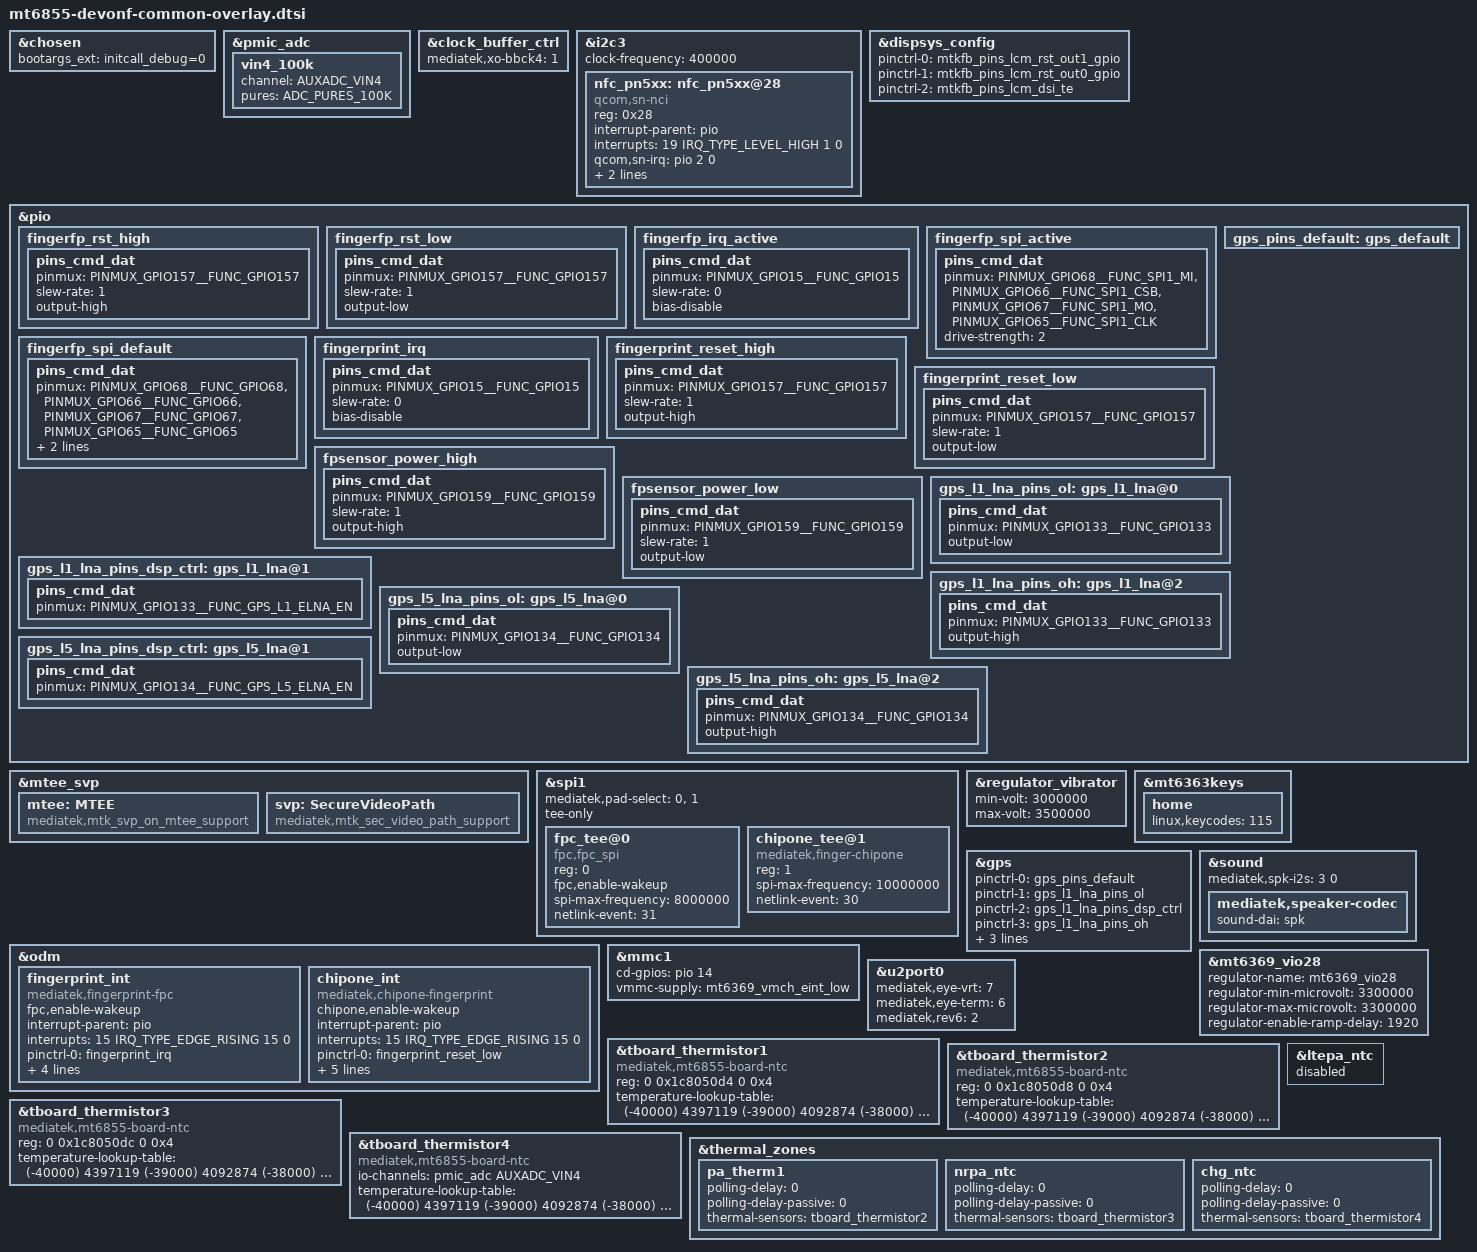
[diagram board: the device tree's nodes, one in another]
/* Copyright (c) 2020, The Linux Foundation. All rights reserved.
 *
 * This program is free software; you can redistribute it and/or modify
 * it under the terms of the GNU General Public License version 2 and
 * only version 2 as published by the Free Software Foundation.
 *
 * This program is distributed in the hope that it will be useful,
 * but WITHOUT ANY WARRANTY; without even the implied warranty of
 * MERCHANTABILITY or FITNESS FOR A PARTICULAR PURPOSE.  See the
 * GNU General Public License for more details.
 */

#include "mediatek/mt6855-moto-common-overlay.dtsi"
#include <dt-bindings/gpio/gpio.h>
#include "mediatek/devonf-display.dtsi"
#include "mediatek/devonf-charger.dtsi"
#include "mediatek/mt6855_devonf_camera_overlay.dtsi"
#include "mediatek/devonf-sar.dtsi"
#include "mediatek/devonf-audio.dtsi"
#include "mediatek/mt6855-moto-memory.dtsi"

#include <dt-bindings/iio/mt635x-auxadc.h>

&chosen {
	bootargs_ext = "initcall_debug=0";
};

&pmic_adc {
	vin4_100k {
		channel = <AUXADC_VIN4>;
		pures = <ADC_PURES_100K>;
	};
};

&clock_buffer_ctrl {
        mediatek,xo-bbck4 = <1>;
};

&i2c3 {
        status = "okay";
        clock-frequency = <400000>;
        nfc_pn5xx: nfc_pn5xx@28 {
                compatible = "qcom,sn-nci";
                reg = <0x28>;
                interrupt-parent = <&pio>;
                interrupts = <19 IRQ_TYPE_LEVEL_HIGH 1 0>;
                qcom,sn-irq = <&pio 2 0>;
                qcom,sn-ven = <&pio 161 0>;
                qcom,sn-firm = <&pio 1 0>;
                status = "okay";
        };
};

&dispsys_config {
	pinctrl-names =
		"lcm_rst_out1_gpio", "lcm_rst_out0_gpio",
		"mode_te_te";
	pinctrl-0 = <&mtkfb_pins_lcm_rst_out1_gpio>;
	pinctrl-1 = <&mtkfb_pins_lcm_rst_out0_gpio>;
	pinctrl-2 = <&mtkfb_pins_lcm_dsi_te>;
	status = "okay";
};

&pio {

	fingerfp_rst_high: fingerfp_rst_high {
		pins_cmd_dat {
			pinmux = <PINMUX_GPIO157__FUNC_GPIO157>;
			slew-rate = <1>;
			output-high;
		};
	};

	fingerfp_rst_low: fingerfp_rst_low {
		pins_cmd_dat {
			pinmux = <PINMUX_GPIO157__FUNC_GPIO157>;
			slew-rate = <1>;
			output-low;
		};
	};

	fingerfp_irq_active: fingerfp_irq_active {
		pins_cmd_dat {
			pinmux = <PINMUX_GPIO15__FUNC_GPIO15>;
			slew-rate = <0>;
			bias-disable;
		};
	};

	fingerfp_spi_active: fingerfp_spi_active {
		pins_cmd_dat {
			pinmux = <PINMUX_GPIO68__FUNC_SPI1_MI>, <PINMUX_GPIO66__FUNC_SPI1_CSB>, <PINMUX_GPIO67__FUNC_SPI1_MO>, <PINMUX_GPIO65__FUNC_SPI1_CLK>;
			drive-strength = <2>;
		};
	};

	fingerfp_spi_default: fingerfp_spi_default {
		pins_cmd_dat {
			pinmux = <PINMUX_GPIO68__FUNC_GPIO68>, <PINMUX_GPIO66__FUNC_GPIO66>, <PINMUX_GPIO67__FUNC_GPIO67>, <PINMUX_GPIO65__FUNC_GPIO65>;
			slew-rate = <1>;
			output-low;
		};
	};
	fingerprint_irq: fingerprint_irq {
		pins_cmd_dat {
			pinmux = <PINMUX_GPIO15__FUNC_GPIO15>;
			slew-rate = <0>;
			bias-disable;
		};
	};

	fingerprint_reset_high: fingerprint_reset_high {
		pins_cmd_dat {
			pinmux = <PINMUX_GPIO157__FUNC_GPIO157>;
			slew-rate = <1>;
			output-high;
		};
	};

	fingerprint_reset_low: fingerprint_reset_low {
		pins_cmd_dat {
			pinmux = <PINMUX_GPIO157__FUNC_GPIO157>;
			slew-rate = <1>;
			output-low;
		};
	};
	fpsensor_power_high: fpsensor_power_high {
		pins_cmd_dat {
			pinmux = <PINMUX_GPIO159__FUNC_GPIO159>;
			slew-rate = <1>;
			output-high;
		};
	};

	fpsensor_power_low: fpsensor_power_low {
		pins_cmd_dat {
			pinmux = <PINMUX_GPIO159__FUNC_GPIO159>;
			slew-rate = <1>;
			output-low;
		};
	};
};

/* SVP */
&mtee_svp {
	mtee: MTEE {
		compatible = "mediatek,mtk_svp_on_mtee_support";
	};
	svp: SecureVideoPath {
		compatible = "mediatek,mtk_sec_video_path_support";
	};
};

/* FINGERPRINT start */
&spi1 {
	status = "okay";
	mediatek,pad-select = <0>, <1>;
	tee-only;

	fpc_tee@0 {
		compatible = "fpc,fpc_spi";
		reg = <0>;
		fpc,enable-wakeup;
		spi-max-frequency = <8000000>;
		netlink-event = <31>;
		status = "okay";
	};

	chipone_tee@1 {
		status = "okay";
		compatible = "mediatek,finger-chipone";
		reg = <1>;
		spi-max-frequency = <10000000>;
		netlink-event = <30>;
	};
};

&odm {
	fingerprint_int: fingerprint_int {
		compatible = "mediatek,fingerprint-fpc";
		fpc,enable-wakeup;
		interrupt-parent = <&pio>;
		interrupts = <15 IRQ_TYPE_EDGE_RISING 15 0>;
		pinctrl-names = "fingerprint_irq", "fingerprint_reset_high", "fingerprint_reset_low";
		pinctrl-0 = <&fingerprint_irq>;
		pinctrl-1 = <&fingerprint_reset_high>;
		pinctrl-2 = <&fingerprint_reset_low>;
		fpc,vdd = <&pio 159 0>;
		fpc,irq = <&pio 15 0>;
		status = "okay";
	};

	chipone_int: chipone_int {
		compatible = "mediatek,chipone-fingerprint";
chipone,enable-wakeup;
		interrupt-parent = <&pio>;
		interrupts = <15 IRQ_TYPE_EDGE_RISING 15 0>;
		pinctrl-names = "fingerprint_reset_low", "fingerprint_reset_high" , "fingerprint_irq", "fpsensor_power_high", "fpsensor_power_low";
		pinctrl-0 = <&fingerprint_reset_low>;
		pinctrl-1 = <&fingerprint_reset_high>;
		pinctrl-2 = <&fingerprint_irq>;
		pinctrl-3= <&fpsensor_power_high>;
		pinctrl-4 = <&fpsensor_power_low>;
		chipone,irq = <&pio 15 0>;
		status = "okay";
	};
};

&regulator_vibrator {
	min-volt = <3000000>;
	max-volt = <3500000>;
	status = "ok";
};

&mt6363keys {
        home {
                linux,keycodes = <115>;
        };
};

/* GPS GPIO standardization start */
&pio {
	gps_pins_default: gps_default {
	};
	gps_l1_lna_pins_ol: gps_l1_lna@0 {
		pins_cmd_dat {
			pinmux = <PINMUX_GPIO133__FUNC_GPIO133>;
			output-low;
		};
	};
	gps_l1_lna_pins_dsp_ctrl: gps_l1_lna@1 {
		pins_cmd_dat {
			pinmux = <PINMUX_GPIO133__FUNC_GPS_L1_ELNA_EN>;
		};
	};
	gps_l1_lna_pins_oh: gps_l1_lna@2 {
		pins_cmd_dat {
			pinmux = <PINMUX_GPIO133__FUNC_GPIO133>;
			output-high;
		};
	};
	gps_l5_lna_pins_ol: gps_l5_lna@0 {
		pins_cmd_dat {
			pinmux = <PINMUX_GPIO134__FUNC_GPIO134>;
			output-low;
		};
	};
	gps_l5_lna_pins_dsp_ctrl: gps_l5_lna@1 {
		pins_cmd_dat {
			pinmux = <PINMUX_GPIO134__FUNC_GPS_L5_ELNA_EN>;
		};
	};
	gps_l5_lna_pins_oh: gps_l5_lna@2 {
		pins_cmd_dat {
			pinmux = <PINMUX_GPIO134__FUNC_GPIO134>;
			output-high;
		};
	};
};



&gps {
	pinctrl-names = "default",
		"gps_l1_lna_disable",
		"gps_l1_lna_dsp_ctrl",
		"gps_l1_lna_enable",
		"gps_l5_lna_disable",
		"gps_l5_lna_dsp_ctrl",
		"gps_l5_lna_enable";
	pinctrl-0 = <&gps_pins_default>;
	pinctrl-1 = <&gps_l1_lna_pins_ol>;
	pinctrl-2 = <&gps_l1_lna_pins_dsp_ctrl>;
	pinctrl-3 = <&gps_l1_lna_pins_oh>;
	pinctrl-4 = <&gps_l5_lna_pins_ol>;
	pinctrl-5 = <&gps_l5_lna_pins_dsp_ctrl>;
	pinctrl-6 = <&gps_l5_lna_pins_oh>;
	status = "okay";
};
/* GPS GPIO standardization end */

//#include "mediatek/cust_mt6855_touch_1080x2400.dtsi"
#include "mediatek/cust_mt6855_camera_v4l2.dtsi"

/delete-node/ &camera_main_two_af_mtk;

&sound {
	mediatek,spk-i2s = <3 0>;
	mediatek,speaker-codec {
		sound-dai = <&spk>;
	};
};

&mmc1 {
	cd-gpios = <&pio 14 GPIO_ACTIVE_HIGH>;
	vmmc-supply = <&mt6369_vmch_eint_low>;
};
#include "devonf-touch.dtsi"

//for alsps sensor tmd2755x
&mt6369_vio28 {
	regulator-name = "mt6369_vio28";
	regulator-min-microvolt = <3300000>;
	regulator-max-microvolt = <3300000>;
	regulator-enable-ramp-delay = <1920>;
};

&u2port0{
	mediatek,eye-vrt = <7>;
	mediatek,eye-term = <6>;
	mediatek,rev6 = <2>;
};


//#include <k6855v1_64/cust.dtsi>
/*End of this file, DO NOT ADD ANYTHING HERE*/

&tboard_thermistor1 {
	compatible = "mediatek,mt6855-board-ntc";
	status = "okay";
	#thermal-sensor-cells = <0>;
	reg = <0 0x1c8050d4 0 0x4>; /* TIA DATA T0 */
	temperature-lookup-table = <
		(-40000) 4397119
		(-39000) 4092874
		(-38000) 3811717
		(-37000) 3551749
		(-36000) 3311236
		(-35000) 3088599
		(-34000) 2882396
		(-33000) 2691310
		(-32000) 2514137
		(-31000) 2349778
		(-30000) 2197225
		(-29000) 2055558
		(-28000) 1923932
		(-27000) 1801573
		(-26000) 1687773
		(-25000) 1581881
		(-24000) 1483100
		(-23000) 1391113
		(-22000) 1305413
		(-21000) 1225531
		(-20000) 1151037
		(-19000) 1081535
		(-18000) 1016661
		(-17000) 956080
		(-16000) 899481
		(-15000) 846579
		(-14000) 797111
		(-13000) 750834
		(-12000) 707524
		(-11000) 666972
		(-10000) 628988
		(-9000) 593342
		(-8000) 559931
		(-7000) 528602
		(-6000) 499212
		(-5000) 471632
		(-4000) 445772
		(-3000) 421480
		(-2000) 398652
		(-1000) 377193
		0 357012
		1000 338006
		2000 320122
		3000 303287
		4000 287434
		5000 272500
		6000 258426
		7000 245160
		8000 232649
		9000 220847
		10000 209710
		11000 199196
		12000 189268
		13000 179890
		14000 171027
		15000 162651
		16000 154726
		17000 147232
		18000 140142
		19000 133432
		20000 127080
		21000 121066
		22000 115368
		23000 109970
		24000 104852
		25000 100000
		26000 95398
		27000 91032
		28000 86889
		29000 82956
		30000 79222
		31000 75675
		32000 72306
		33000 69104
		34000 66061
		35000 63167
		36000 60415
		37000 57797
		38000 55306
		39000 52934
		40000 50677
		41000 48528
		42000 46482
		43000 44533
		44000 42675
		45000 40904
		46000 39213
		47000 37601
		48000 36063
		49000 34595
		50000 33195
		51000 31859
		52000 30584
		53000 29366
		54000 28203
		55000 27091
		56000 26028
		57000 25013
		58000 24042
		59000 23113
		60000 22224
		61000 21374
		62000 20560
		63000 19782
		64000 19036
		65000 18322
		66000 17640
		67000 16986
		68000 16360
		69000 15759
		70000 15184
		71000 14631
		72000 14100
		73000 13591
		74000 13103
		75000 12635
		76000 12187
		77000 11756
		78000 11343
		79000 10946
		80000 10565
		81000 10199
		82000 9847
		83000 9509
		84000 9184
		85000 8872
		86000 8572
		87000 8283
		88000 8005
		89000 7738
		90000 7481
		91000 7234
		92000 6997
		93000 6769
		94000 6548
		95000 6337
		96000 6132
		97000 5934
		98000 5744
		99000 5561
		100000 5384
		101000 5214
		102000 5051
		103000 4893
		104000 4741
		105000 4594
		106000 4453
		107000 4316
		108000 4184
		109000 4057
		110000 3934
		111000 3816
		112000 3701
		113000 3591
		114000 3484
		115000 3380
		116000 3281
		117000 3185
		118000 3093
		119000 3003
		120000 2916
		121000 2832
		122000 2751
		123000 2672
		124000 2596
		125000 2522>;
};

&tboard_thermistor2 {
	compatible = "mediatek,mt6855-board-ntc";
	status = "okay";
	#thermal-sensor-cells = <0>;
	reg = <0 0x1c8050d8 0 0x4>; /* TIA DATA T1 */
	temperature-lookup-table = <
		(-40000) 4397119
		(-39000) 4092874
		(-38000) 3811717
		(-37000) 3551749
		(-36000) 3311236
		(-35000) 3088599
		(-34000) 2882396
		(-33000) 2691310
		(-32000) 2514137
		(-31000) 2349778
		(-30000) 2197225
		(-29000) 2055558
		(-28000) 1923932
		(-27000) 1801573
		(-26000) 1687773
		(-25000) 1581881
		(-24000) 1483100
		(-23000) 1391113
		(-22000) 1305413
		(-21000) 1225531
		(-20000) 1151037
		(-19000) 1081535
		(-18000) 1016661
		(-17000) 956080
		(-16000) 899481
		(-15000) 846579
		(-14000) 797111
		(-13000) 750834
		(-12000) 707524
		(-11000) 666972
		(-10000) 628988
		(-9000) 593342
		(-8000) 559931
		(-7000) 528602
		(-6000) 499212
		(-5000) 471632
		(-4000) 445772
		(-3000) 421480
		(-2000) 398652
		(-1000) 377193
		0 357012
		1000 338006
		2000 320122
		3000 303287
		4000 287434
		5000 272500
		6000 258426
		7000 245160
		8000 232649
		9000 220847
		10000 209710
		11000 199196
		12000 189268
		13000 179890
		14000 171027
		15000 162651
		16000 154726
		17000 147232
		18000 140142
		19000 133432
		20000 127080
		21000 121066
		22000 115368
		23000 109970
		24000 104852
		25000 100000
		26000 95398
		27000 91032
		28000 86889
		29000 82956
		30000 79222
		31000 75675
		32000 72306
		33000 69104
		34000 66061
		35000 63167
		36000 60415
		37000 57797
		38000 55306
		39000 52934
		40000 50677
		41000 48528
		42000 46482
		43000 44533
		44000 42675
		45000 40904
		46000 39213
		47000 37601
		48000 36063
		49000 34595
		50000 33195
		51000 31859
		52000 30584
		53000 29366
		54000 28203
		55000 27091
		56000 26028
		57000 25013
		58000 24042
		59000 23113
		60000 22224
		61000 21374
		62000 20560
		63000 19782
		64000 19036
		65000 18322
		66000 17640
		67000 16986
		68000 16360
		69000 15759
		70000 15184
		71000 14631
		72000 14100
		73000 13591
		74000 13103
		75000 12635
		76000 12187
		77000 11756
		78000 11343
		79000 10946
		80000 10565
		81000 10199
		82000 9847
		83000 9509
		84000 9184
		85000 8872
		86000 8572
		87000 8283
		88000 8005
		89000 7738
		90000 7481
		91000 7234
		92000 6997
		93000 6769
		94000 6548
		95000 6337
		96000 6132
		97000 5934
		98000 5744
		99000 5561
		100000 5384
		101000 5214
		102000 5051
		103000 4893
		104000 4741
		105000 4594
		106000 4453
		107000 4316
		108000 4184
		109000 4057
		110000 3934
		111000 3816
		112000 3701
		113000 3591
		114000 3484
		115000 3380
		116000 3281
		117000 3185
		118000 3093
		119000 3003
		120000 2916
		121000 2832
		122000 2751
		123000 2672
		124000 2596
		125000 2522>;
};

&tboard_thermistor3 {
	compatible = "mediatek,mt6855-board-ntc";
	status = "okay";
	#thermal-sensor-cells = <0>;
	reg = <0 0x1c8050dc 0 0x4>; /* TIA DATA T2 */
	temperature-lookup-table = <
		(-40000) 4397119
		(-39000) 4092874
		(-38000) 3811717
		(-37000) 3551749
		(-36000) 3311236
		(-35000) 3088599
		(-34000) 2882396
		(-33000) 2691310
		(-32000) 2514137
		(-31000) 2349778
		(-30000) 2197225
		(-29000) 2055558
		(-28000) 1923932
		(-27000) 1801573
		(-26000) 1687773
		(-25000) 1581881
		(-24000) 1483100
		(-23000) 1391113
		(-22000) 1305413
		(-21000) 1225531
		(-20000) 1151037
		(-19000) 1081535
		(-18000) 1016661
		(-17000) 956080
		(-16000) 899481
		(-15000) 846579
		(-14000) 797111
		(-13000) 750834
		(-12000) 707524
		(-11000) 666972
		(-10000) 628988
		(-9000) 593342
		(-8000) 559931
		(-7000) 528602
		(-6000) 499212
		(-5000) 471632
		(-4000) 445772
		(-3000) 421480
		(-2000) 398652
		(-1000) 377193
		0 357012
		1000 338006
		2000 320122
		3000 303287
		4000 287434
		5000 272500
		6000 258426
		7000 245160
		8000 232649
		9000 220847
		10000 209710
		11000 199196
		12000 189268
		13000 179890
		14000 171027
		15000 162651
		16000 154726
		17000 147232
		18000 140142
		19000 133432
		20000 127080
		21000 121066
		22000 115368
		23000 109970
		24000 104852
		25000 100000
		26000 95398
		27000 91032
		28000 86889
		29000 82956
		30000 79222
		31000 75675
		32000 72306
		33000 69104
		34000 66061
		35000 63167
		36000 60415
		37000 57797
		38000 55306
		39000 52934
		40000 50677
		41000 48528
		42000 46482
		43000 44533
		44000 42675
		45000 40904
		46000 39213
		47000 37601
		48000 36063
		49000 34595
		50000 33195
		51000 31859
		52000 30584
		53000 29366
		54000 28203
		55000 27091
		56000 26028
		57000 25013
		58000 24042
		59000 23113
		60000 22224
		61000 21374
		62000 20560
		63000 19782
		64000 19036
		65000 18322
		66000 17640
		67000 16986
		68000 16360
		69000 15759
		70000 15184
		71000 14631
		72000 14100
		73000 13591
		74000 13103
		75000 12635
		76000 12187
		77000 11756
		78000 11343
		79000 10946
		80000 10565
		81000 10199
		82000 9847
		83000 9509
		84000 9184
		85000 8872
		86000 8572
		87000 8283
		88000 8005
		89000 7738
		90000 7481
		91000 7234
		92000 6997
		93000 6769
		94000 6548
		95000 6337
		96000 6132
		97000 5934
		98000 5744
		99000 5561
		100000 5384
		101000 5214
		102000 5051
		103000 4893
		104000 4741
		105000 4594
		106000 4453
		107000 4316
		108000 4184
		109000 4057
		110000 3934
		111000 3816
		112000 3701
		113000 3591
		114000 3484
		115000 3380
		116000 3281
		117000 3185
		118000 3093
		119000 3003
		120000 2916
		121000 2832
		122000 2751
		123000 2672
		124000 2596
		125000 2522>;
};

&tboard_thermistor4 {
	compatible = "mediatek,mt6855-board-ntc";
	status = "okay";
	#thermal-sensor-cells = <0>;
	io-channels = <&pmic_adc AUXADC_VIN4>;
	io-channel-names = "Charger_NTC";
	temperature-lookup-table = <
		(-40000) 4397119
		(-39000) 4092874
		(-38000) 3811717
		(-37000) 3551749
		(-36000) 3311236
		(-35000) 3088599
		(-34000) 2882396
		(-33000) 2691310
		(-32000) 2514137
		(-31000) 2349778
		(-30000) 2197225
		(-29000) 2055558
		(-28000) 1923932
		(-27000) 1801573
		(-26000) 1687773
		(-25000) 1581881
		(-24000) 1483100
		(-23000) 1391113
		(-22000) 1305413
		(-21000) 1225531
		(-20000) 1151037
		(-19000) 1081535
		(-18000) 1016661
		(-17000) 956080
		(-16000) 899481
		(-15000) 846579
		(-14000) 797111
		(-13000) 750834
		(-12000) 707524
		(-11000) 666972
		(-10000) 628988
		(-9000) 593342
		(-8000) 559931
		(-7000) 528602
		(-6000) 499212
		(-5000) 471632
		(-4000) 445772
		(-3000) 421480
		(-2000) 398652
		(-1000) 377193
		0 357012
		1000 338006
		2000 320122
		3000 303287
		4000 287434
		5000 272500
		6000 258426
		7000 245160
		8000 232649
		9000 220847
		10000 209710
		11000 199196
		12000 189268
		13000 179890
		14000 171027
		15000 162651
		16000 154726
		17000 147232
		18000 140142
		19000 133432
		20000 127080
		21000 121066
		22000 115368
		23000 109970
		24000 104852
		25000 100000
		26000 95398
		27000 91032
		28000 86889
		29000 82956
		30000 79222
		31000 75675
		32000 72306
		33000 69104
		34000 66061
		35000 63167
		36000 60415
		37000 57797
		38000 55306
		39000 52934
		40000 50677
		41000 48528
		42000 46482
		43000 44533
		44000 42675
		45000 40904
		46000 39213
		47000 37601
		48000 36063
		49000 34595
		50000 33195
		51000 31859
		52000 30584
		53000 29366
		54000 28203
		55000 27091
		56000 26028
		57000 25013
		58000 24042
		59000 23113
		60000 22224
		61000 21374
		62000 20560
		63000 19782
		64000 19036
		65000 18322
		66000 17640
		67000 16986
		68000 16360
		69000 15759
		70000 15184
		71000 14631
		72000 14100
		73000 13591
		74000 13103
		75000 12635
		76000 12187
		77000 11756
		78000 11343
		79000 10946
		80000 10565
		81000 10199
		82000 9847
		83000 9509
		84000 9184
		85000 8872
		86000 8572
		87000 8283
		88000 8005
		89000 7738
		90000 7481
		91000 7234
		92000 6997
		93000 6769
		94000 6548
		95000 6337
		96000 6132
		97000 5934
		98000 5744
		99000 5561
		100000 5384
		101000 5214
		102000 5051
		103000 4893
		104000 4741
		105000 4594
		106000 4453
		107000 4316
		108000 4184
		109000 4057
		110000 3934
		111000 3816
		112000 3701
		113000 3591
		114000 3484
		115000 3380
		116000 3281
		117000 3185
		118000 3093
		119000 3003
		120000 2916
		121000 2832
		122000 2751
		123000 2672
		124000 2596
		125000 2522>;
};

&ltepa_ntc {
	status = "disabled";
};

&thermal_zones{
//		ap_ntc: ap_ntc {
//			polling-delay = <0>; /* milliseconds */
//			polling-delay-passive = <0>; /* milliseconds */
//			thermal-sensors = <&tboard_thermistor1>;
//		};
		pa_therm1: pa_therm1 {
			polling-delay = <0>; /* milliseconds */
			polling-delay-passive = <0>; /* milliseconds */
			thermal-sensors = <&tboard_thermistor2>;
		};
		nrpa_ntc: nrpa_ntc {
			polling-delay = <0>; /* milliseconds */
			polling-delay-passive = <0>; /* milliseconds */
			thermal-sensors = <&tboard_thermistor3>;
		};
		chg_ntc {
			polling-delay = <0>; /* milliseconds */
			polling-delay-passive = <0>; /* milliseconds */
			thermal-sensors = <&tboard_thermistor4>;
		};
};
